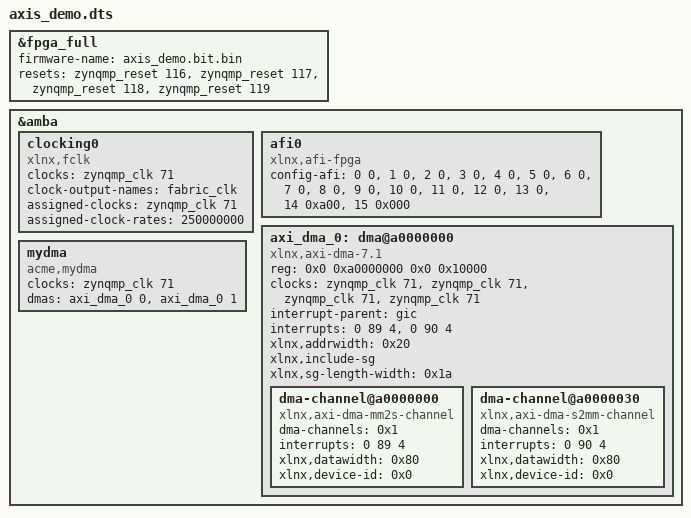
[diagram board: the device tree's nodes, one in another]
// Device tree overlay for the axis_demo PL design (hw/axis_demo/build_bd.tcl)
// on the KV260 (PetaLinux 2022.2). Loaded by `xmutil loadapp axis_demo`.
//
// Package:  APP=axis_demo bash hw/package.sh hw/axis_demo/axis_demo.bit
//
// The only CPU-visible thing in the PL is the DMA:
//   axi_dma_0 @ 0xA000_0000  AXI DMA, MM2S + S2MM, 128-bit, on HP0.
//             Owned by xilinx_dma; mydma.ko borrows its channels.
// axis_demo sits on the DMA's streams and has no registers or node.
/dts-v1/;
/plugin/;

/ {
	/* Fragment 0: program the PL with the bitstream in this app's folder. */
	fragment@0 {
		target = <&fpga_full>;
		__overlay__ {
			#address-cells = <2>;
			#size-cells = <2>;
			firmware-name = "axis_demo.bit.bin";
			resets = <&zynqmp_reset 116>, <&zynqmp_reset 117>,
				 <&zynqmp_reset 118>, <&zynqmp_reset 119>;
		};
	};

	/* Fragment 1: describe what is in the PL, under the PS's AXI bus. */
	fragment@1 {
		target = <&amba>;
		__overlay__ {
			#address-cells = <2>;
			#size-cells = <2>;

			/* pl_clk0. mydma.ko also sets 250 MHz at load (pl_clk_hz). */
			clocking0: clocking0 {
				compatible = "xlnx,fclk";
				#clock-cells = <0>;
				clocks = <&zynqmp_clk 71>;
				clock-output-names = "fabric_clk";
				assigned-clocks = <&zynqmp_clk 71>;
				assigned-clock-rates = <250000000>;	/* 250 MHz */
			};

			/* PS-PL port widths, same as multi_hp (all 128-bit). */
			afi0: afi0 {
				compatible = "xlnx,afi-fpga";
				config-afi = <0 0>, <1 0>, <2 0>, <3 0>, <4 0>, <5 0>,
					     <6 0>, <7 0>, <8 0>, <9 0>, <10 0>, <11 0>,
					     <12 0>, <13 0>, <14 0xa00>, <15 0x000>;
			};

			axi_dma_0: dma@a0000000 {
				compatible = "xlnx,axi-dma-7.1", "xlnx,axi-dma-1.00.a";
				reg = <0x0 0xa0000000 0x0 0x10000>;
				#dma-cells = <1>;
				clock-names = "s_axi_lite_aclk", "m_axi_sg_aclk", "m_axi_mm2s_aclk", "m_axi_s2mm_aclk";
				clocks = <&zynqmp_clk 71>, <&zynqmp_clk 71>, <&zynqmp_clk 71>, <&zynqmp_clk 71>;
				interrupt-names = "mm2s_introut", "s2mm_introut";
				interrupt-parent = <&gic>;
				interrupts = <0 89 4>, <0 90 4>;	/* pl_ps_irq0[0], [1] */
				xlnx,addrwidth = <0x20>;		/* c_addr_width 32 */
				xlnx,include-sg;			/* c_include_sg 1 */
				xlnx,sg-length-width = <0x1a>;		/* c_sg_length_width 26 */

				dma-channel@a0000000 {
					compatible = "xlnx,axi-dma-mm2s-channel";
					dma-channels = <0x1>;
					interrupts = <0 89 4>;
					xlnx,datawidth = <0x80>;	/* 128-bit stream */
					xlnx,device-id = <0x0>;
				};

				dma-channel@a0000030 {
					compatible = "xlnx,axi-dma-s2mm-channel";
					dma-channels = <0x1>;
					interrupts = <0 90 4>;
					xlnx,datawidth = <0x80>;	/* 128-bit stream */
					xlnx,device-id = <0x0>;
				};
			};

			/* Binds mydma.ko to the DMA's two channels; creates /dev/mydma. */
			mydma {
				compatible = "acme,mydma";
				clocks = <&zynqmp_clk 71>;
				clock-names = "pl0";
				dmas = <&axi_dma_0 0>, <&axi_dma_0 1>;	/* 0 = MM2S, 1 = S2MM */
				dma-names = "tx", "rx";
			};
		};
	};
};
